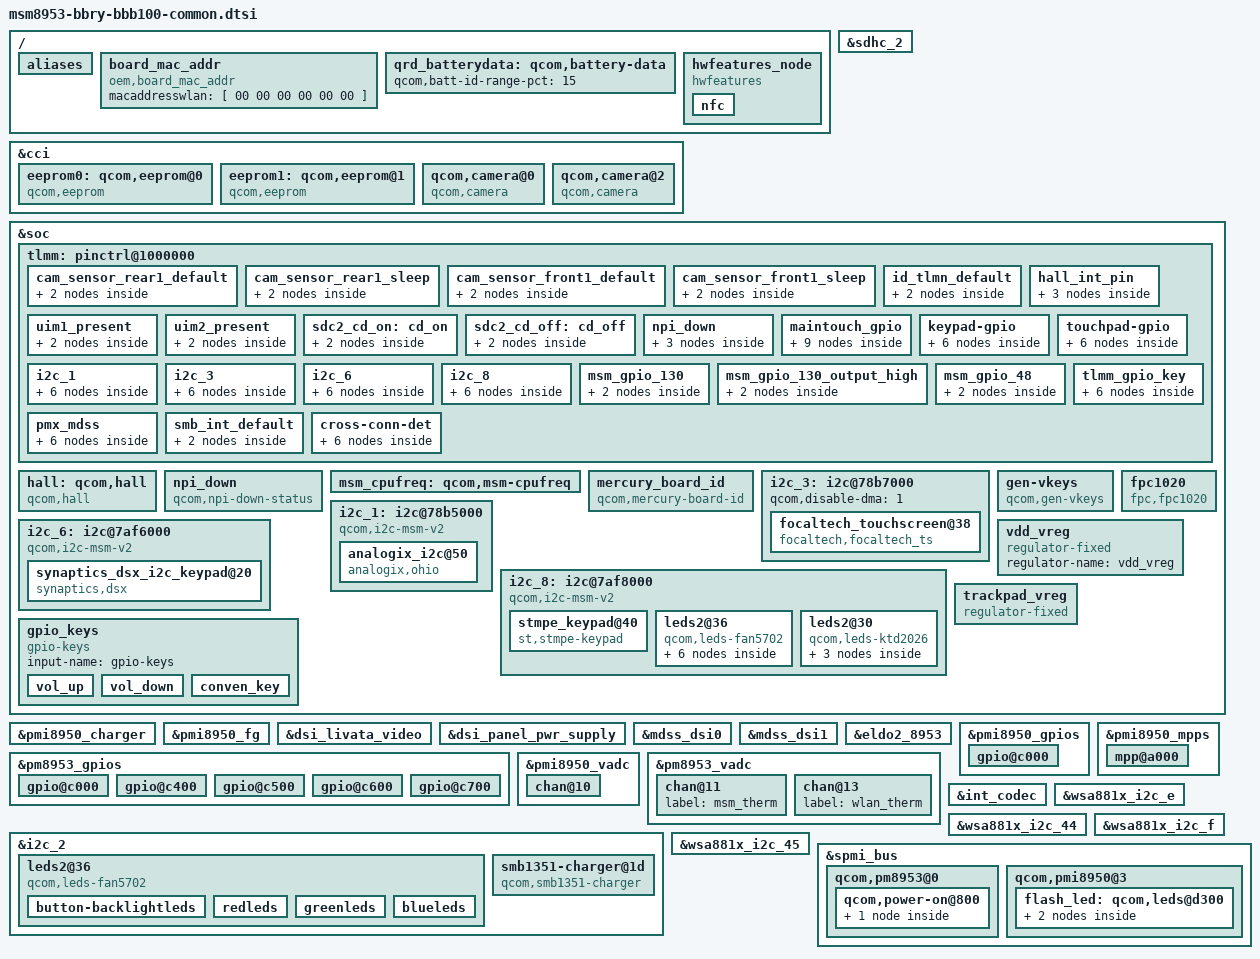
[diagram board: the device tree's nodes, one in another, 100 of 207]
/* Copyright (C) 2016 BlackBerry Limited. All rights reserved.
 * Copyright (c) 2014, The Linux Foundation. All rights reserved.
 *
 * This program is free software; you can redistribute it and/or modify
 * it under the terms of the GNU General Public License version 2 and
 * only version 2 as published by the Free Software Foundation.
 *
 * This program is distributed in the hope that it will be useful,
 * but WITHOUT ANY WARRANTY; without even the implied warranty of
 * MERCHANTABILITY or FITNESS FOR A PARTICULAR PURPOSE.  See the
 * GNU General Public License for more details.
 */

/*
 *  This DTSI is used for content that is common to all revisions of BBB100
 */
#include "dsi-panel-livata-video.dtsi"

/ {
	aliases {
		i2c1 = &i2c_1;
		i2c6 = &i2c_6;
		i2c8 = &i2c_8;
	};

	board_mac_addr {
		compatible = "oem,board_mac_addr";
		macaddresswlan = [ 00 00 00 00 00 00 ]; /* Filled by bootchain */
	};
};

&cci {
        /* MODIFIED-BEGIN by yongzhi.li, 2016-09-02,BUG-2641941*/
        /delete-node/qcom,eeprom@0;
        eeprom0: qcom,eeprom@0 {
		cell-index = <0>;
		compatible = "qcom,eeprom";
		qcom,cci-master = <0>;
		reg = <0x0>;
		cam_vio-supply = <&pm8953_l6>;
		cam_vdig-supply = <&pm8953_l2>;
		cam_vana-supply =  <&pm8953_l17>;
		qcom,cam-vreg-name = "cam_vio",  "cam_vdig",  "cam_vana";
		qcom,cam-vreg-min-voltage = <1800000 1100000 2850000>;
		qcom,cam-vreg-max-voltage = <1800000 1100000 2850000>;
		qcom,cam-vreg-op-mode = <0 105000 100000>;
		pinctrl-names = "cam_default", "cam_suspend";
		pinctrl-0 = <&cam_sensor_mclk0_default
				&cam_sensor_rear1_default>;
		pinctrl-1 = <&cam_sensor_mclk0_sleep &cam_sensor_rear1_sleep>;

		gpios = <&tlmm 26 0>,
			<&tlmm 40 0>,
			<&tlmm 35 0>;
		qcom,gpio-reset = <1>;
		qcom,gpio-vaf = <2>;
		qcom,gpio-req-tbl-num = <0 1 2>;
		qcom,gpio-req-tbl-flags = <1 0 0>;
		qcom,gpio-req-tbl-label = "CAMIF_MCLK0",
			"CAM_RESET0",
			"CAM_VAF";
		status = "ok";
		clocks = <&clock_gcc clk_mclk0_clk_src>,
				<&clock_gcc clk_gcc_camss_mclk0_clk>;
		clock-names = "cam_src_clk", "cam_clk";
		qcom,clock-rates = <24000000 0>;
	};
	/delete-node/qcom,eeprom@1;
         eeprom1: qcom,eeprom@1 {
		cell-index = <1>;
		reg = <0x1>;
		compatible = "qcom,eeprom";
		qcom,cci-master = <0>;
		cam_vdig-supply = <&pm8953_l23>;
		cam_vio-supply = <&pm8953_l6>;
                cam_vana-supply =  <&pm8953_l22>;
		qcom,cam-vreg-name = "cam_vdig", "cam_vio", "cam_vana";
		qcom,cam-vreg-min-voltage = <1200000 0 2800000>;
		qcom,cam-vreg-max-voltage = <1200000 0 2800000>;
		qcom,cam-vreg-op-mode = <105000 0 80000 >;
		pinctrl-names = "cam_default", "cam_suspend";
		pinctrl-0 = <&cam_sensor_mclk1_default
				&cam_sensor_front1_default>;
		pinctrl-1 = <&cam_sensor_mclk1_sleep &cam_sensor_front1_sleep>;
		gpios = <&tlmm 27 0>,
			<&tlmm 129 0>;
		qcom,gpio-reset = <1>;
		qcom,gpio-req-tbl-num = <0 1 >;
		qcom,gpio-req-tbl-flags = <1 0 >;
		qcom,gpio-req-tbl-label = "CAMIF_MCLK2",
			"CAM_RESET2";
		status = "ok";
		clocks = <&clock_gcc clk_mclk1_clk_src>,
				<&clock_gcc clk_gcc_camss_mclk1_clk>;
		clock-names = "cam_src_clk", "cam_clk";
		qcom,clock-rates = <19200000 0>;
	};
        /delete-node/qcom,camera@0;
        qcom,camera@0{
		cell-index = <0>;
		compatible = "qcom,camera";
		reg = <0x0>;
		qcom,csiphy-sd-index = <0>;
		qcom,csid-sd-index = <0>;
		qcom,mount-angle = <90>;
		qcom,led-flash-src = <&led_flash0>;
		qcom,eeprom-src = <&eeprom0>;
		qcom,actuator-src = <&actuator0>;
                cam_vio-supply = <&pm8953_l6>;
		cam_vdig-supply = <&pm8953_l2>;
		cam_vana-supply = <&pm8953_l17>;
		qcom,cam-vreg-name = "cam_vio", "cam_vdig", "cam_vana";
		qcom,cam-vreg-min-voltage = <1800000 1100000 2850000>;
		qcom,cam-vreg-max-voltage = <1800000 1100000 2850000>;
		qcom,cam-vreg-op-mode = <0   105000 100000>;
		pinctrl-names = "cam_default", "cam_suspend";
		pinctrl-0 = <&cam_sensor_mclk0_default
				&cam_sensor_rear1_default>;
		pinctrl-1 = <&cam_sensor_mclk0_sleep &cam_sensor_rear1_sleep>;
		gpios = <&tlmm 26 0>,
			<&tlmm 40 0>,
                        <&tlmm 35 0>;
		qcom,gpio-reset = <1>;
                qcom,gpio-vaf = <2>;
		qcom,gpio-req-tbl-num = <0 1 2>;
		qcom,gpio-req-tbl-flags = <1 0 0>;
		qcom,gpio-req-tbl-label = "CAMIF_MCLK0",
			"CAM_RESET0",
			"CAM_VAF";
		qcom,sensor-position = <0>;
		qcom,sensor-mode = <0>;
		qcom,cci-master = <0>;
		status = "ok";
		clocks = <&clock_gcc clk_mclk0_clk_src>,
				<&clock_gcc clk_gcc_camss_mclk0_clk>;
		clock-names = "cam_src_clk", "cam_clk";
		qcom,clock-rates = <24000000 0>;
	};
         /delete-node/qcom,camera@2;
	qcom,camera@2 {
		cell-index = <2>;
		compatible = "qcom,camera";
		reg = <0x02>;
		qcom,csiphy-sd-index = <2>;
		qcom,csid-sd-index = <2>;
		qcom,mount-angle = <90>;
                qcom,led-flash-src = <&led_flash0>; // MODIFIED by yongzhi.li, 2016-12-16,BUG-3767349
		qcom,eeprom-src = <&eeprom1>;
		qcom,actuator-src = <&actuator1>;
		cam_vdig-supply = <&pm8953_l23>;
		cam_vio-supply = <&pm8953_l6>;
		cam_vana-supply = <&pm8953_l22>;
		qcom,cam-vreg-name = "cam_vdig", "cam_vio", "cam_vana";
		qcom,cam-vreg-min-voltage = <1200000 0 2800000 >;
		qcom,cam-vreg-max-voltage = <1200000 0 2800000 >;
		qcom,cam-vreg-op-mode = <105000 0 80000 >;
		qcom,gpio-no-mux = <0>;
		pinctrl-names = "cam_default", "cam_suspend";
		pinctrl-0 = <&cam_sensor_mclk1_default
				&cam_sensor_front1_default>;
		pinctrl-1 = <&cam_sensor_mclk1_sleep
				&cam_sensor_front1_sleep>;
		gpios = <&tlmm 27 0>,
			<&tlmm 129 0>;
		qcom,gpio-reset = <1>;
		qcom,gpio-req-tbl-num = <0 1 >;
		qcom,gpio-req-tbl-flags = <1 0 >;
		qcom,gpio-req-tbl-label = "CAMIF_MCLK2",
					  "CAM_RESET2";
		qcom,sensor-position = <1>;
		qcom,sensor-mode = <0>;
		qcom,cci-master = <1>;
		status = "ok";
		clocks = <&clock_gcc clk_mclk1_clk_src>,
			<&clock_gcc clk_gcc_camss_mclk1_clk>;
		clock-names = "cam_src_clk", "cam_clk";
		qcom,clock-rates = <24000000 0>;
		/* MODIFIED-END by yongzhi.li,BUG-2641941*/
	};
};

/* Changes to msm8993-pinctrl.dtsi for bbry-bb100 platform */
&sdhc_2 {
	cd-gpios = <&tlmm 133 GPIO_ACTIVE_HIGH>;

	pinctrl-names = "active", "sleep", "onetime";
	pinctrl-2 = <&uim1_present &uim2_present>;
};

&tlmm {
	hall_int_pin {
		hall_default: hall_default {
			mux {
				pins = "gpio131", "gpio140";
				function = "gpio";
			};

			config {
				pins = "gpio131", "gpio140";
				drive-strength = <2>;
				bias-disable;
				input-enable;
			};
		};
	};

	uim1_present: uim1_present {
		mux {
			pins = "gpio54";
			function = "uim1_present";
		};

		config {
			pins = "gpio54";
			drive-strength = <2>;
			bias-pull-up;
		};
	};

	uim2_present: uim2_present {
		mux {
			pins = "gpio58";
			function = "uim2_present";
		};

		config {
			pins = "gpio58";
			drive-strength = <2>;
			bias-pull-up;
		};
	};

	sdc2_cd_on: cd_on {
		mux {
			pins = "gpio133";
			function = "gpio";
		};

		config {
			pins = "gpio133";
			drive-strength = <2>;
			bias-pull-up;
			input-enable;
		};
	};

	sdc2_cd_off: cd_off {
		mux {
			pins = "gpio133";
			function = "gpio";
		};

		config {
			pins = "gpio133";
			drive-strength = <2>;
			bias-pull-up;
			input-enable;
		};
	};

	npi_down {
		npi_down_default: npi_down_default{
			mux {
				pins = "gpio89";
				function = "gpio";
			};

			config {
				pins = "gpio89";
				drive-strength = <2>; /* 2 mA */
				bias-pull-up; /* pull up */
				input-enable;
			};
		};
	};
	maintouch_gpio {
		focaltech_irq: focaltech_irq {
			mux {
				pins = "gpio65";
				function = "gpio";
			};

			config {
				pins = "gpio65";
				drive-strength = <2>;
				bias-pull-up;
			};
		};

		focaltech_reset: focaltech_reset {
			mux {
				pins = "gpio64";
				function = "gpio";
			};

			config {
				pins = "gpio64";
				drive-strength = <2>;
				bias-pull-up;
			};
		};

		focaltech_input: focaltech_input {
			mux {
				pins = "gpio85", "gpio86", "gpio87";
				function = "gpio";
			};

			config {
				pins = "gpio85", "gpio86", "gpio87";
				drive-strength = <2>;
				bias-pull-up;
			};
		};
	};

	/* KEYPAD INTERRUPT */
	keypad-gpio {
		keypad_int_default: keypad_int_default {
			mux {
				pins = "gpio12";
				function = "gpio";
			};

			config {
				pins = "gpio12";
				drive-strength = <2>;
				bias-pull-up;
			};
		};
		keypad_reset_default: keypad_reset_default {
			mux {
				pins = "gpio66";
				function = "gpio";
			};

			config {
				pins = "gpio66";
				drive-strength = <2>;
				bias-pull-up;
			};
		};
	};

	touchpad-gpio {
		touchpad_int_default: touchpad_int_default {
			mux {
				pins = "gpio21";
				function = "gpio";
			};

			config {
				pins = "gpio21";
				drive-strength = <2>;
				bias-pull-up;
			};
		};
		touchpad_reset: touchpad_reset {
			mux {
				pins = "gpio20";
				function = "gpio";
			};

			config {
				pins = "gpio20";
				drive-strength = <2>;
				bias-pull-up;
			};
		};
	};

	i2c_1 {
		i2c_1_active: i2c_1_active {
			mux {
				pins = "gpio2", "gpio3";
				function = "blsp_i2c1";
			};
			config {
				pins = "gpio2", "gpio3";
				drive-strength = <2>;
				bias-disable;
			};
		};

		i2c_1_sleep: i2c_1_sleep {
			mux {
				pins = "gpio2", "gpio3";
				function = "blsp_i2c1";
			};
			config {
				pins = "gpio2", "gpio3";
				drive-strength = <2>;
				bias-pull-up;
			};
		};
	};

	i2c_3 {
		i2c_3_active: i2c_3_active {
			/* active state */
			mux {
				pins = "gpio10", "gpio11";
				function = "blsp_i2c3";
			};

			config {
				pins = "gpio10", "gpio11";
				drive-strength = <2>;
				bias-disable;
			};
		};

		i2c_3_sleep: i2c_3_sleep {
			/* suspended state */
			mux {
				pins = "gpio10", "gpio11";
				function = "blsp_i2c3";
			};

			config {
				pins = "gpio10", "gpio11";
				drive-strength = <2>;
				bias-disable;
			};
		};
	};

	i2c_6 {
		i2c_6_active: i2c_6_active {
			/* active state */
			mux {
				pins = "gpio22", "gpio23";
				function = "blsp_i2c6";
			};

			config {
				pins = "gpio22", "gpio23";
				drive-strength = <2>;
				bias-disable;
			};
		};

		i2c_6_sleep: i2c_6_sleep {
			/* suspended state */
			mux {
				pins = "gpio22", "gpio23";
				function = "blsp_i2c6";
			};

			config {
				pins = "gpio22", "gpio23";
				drive-strength = <2>;
				bias-disable;
			};
		};
	};

	i2c_8 {
		i2c_8_active: i2c_8_active {
			/* active state */
			mux {
				pins = "gpio98", "gpio99";
				function = "blsp_i2c8";
			};

			config {
				pins = "gpio99", "gpio98";
				drive-strength = <2>;
				bias-disable;
			};
		};

		i2c_8_sleep: i2c_8_sleep {
			/* suspended state */
			mux {
				pins = "gpio98", "gpio99";
				function = "blsp_i2c8";
			};

			config {
				pins = "gpio99", "gpio98";
				drive-strength = <2>;
				bias-disable;
			};
		};
	};

	/* GPIO_130 : FP_RESET_N */
	msm_gpio_130: msm_gpio_130 {
		mux {
		        pins = "gpio130";
               		function = "gpio";
		};

		config {
		        pins = "gpio130";
		        drive-strength = <2>;
		        bias-disable;
		        output-low;
		};
       	};

       	/* GPIO_130 : FP_RESET_N, state device active*/
        msm_gpio_130_output_high: msm_gpio_130_output_high {
		mux {
		        pins = "gpio130";
		        function = "gpio";
		};

		config {
		        pins = "gpio130";
		        drive-strength = <2>;
                       	bias-disable;
       	                output-high;
               	};
       	};

        /* GPIO_48 : FP_INT_N */
       	msm_gpio_48: msm_gpio_48 {
		mux {
                       	pins = "gpio48";
                       	function = "gpio";
               	};

		config {
                       	pins = "gpio48";
                       	drive-strength = <2>;
                       	bias-pull-down;
                };
	};

	tlmm_gpio_key {
		gpio_key_active: gpio_key_active {
			mux {
				/* MODIFIED-BEGIN by Haojun Chen, 2016-11-29,BUG-3620552*/
				pins = "gpio85", "gpio87", "gpio88";
				function = "gpio";
			};

			config {
				pins = "gpio85", "gpio87", "gpio88";
				/* MODIFIED-END by Haojun Chen,BUG-3620552*/
				drive-strength = <2>;
				bias-pull-up;
			};
		};

		gpio_key_suspend: gpio_key_suspend {
			mux {
				/* MODIFIED-BEGIN by Haojun Chen, 2016-11-29,BUG-3620552*/
				pins = "gpio85", "gpio87", "gpio88";
				function = "gpio";
			};

			config {
				pins = "gpio85", "gpio87", "gpio88";
				/* MODIFIED-END by Haojun Chen,BUG-3620552*/
				drive-strength = <2>;
				bias-pull-up;
			};
		};
	};
};

&soc {
        tlmm: pinctrl@1000000{
                cam_sensor_rear1_default: cam_sensor_rear1_default {
			/* RESET, STANDBY */
			mux {
				pins = "gpio40", "gpio39", "gpio35";
				function = "gpio";
			};

			config {
				pins = "gpio40","gpio39", "gpio35";
				bias-disable; /* No PULL */
				drive-strength = <2>; /* 2 MA */
			};
		};

		cam_sensor_rear1_sleep: cam_sensor_rear1_sleep {
			/* RESET, STANDBY */
			mux {
				pins = "gpio40","gpio39", "gpio35";
				function = "gpio";
			};

			config {
				pins = "gpio40","gpio39", "gpio35";
				bias-disable; /* No PULL */
				drive-strength = <2>; /* 2 MA */
			};
		};

                /* MODIFIED-BEGIN by yongzhi.li, 2017-03-14,BUG-4304800*/
                /delete-node/cam_sensor_front1_default;
                cam_sensor_front1_default: cam_sensor_front1_default {  //yongzhi
			/* RESET, STANDBY */
			mux {
				pins = "gpio129";
				function = "gpio";
			};

			config {
				pins = "gpio129";
				bias-disable; /* No PULL */
				drive-strength = <2>; /* 2 MA */
			};
		};

                /delete-node/cam_sensor_front1_sleep;
		cam_sensor_front1_sleep: cam_sensor_front1_sleep {
			/* RESET, STANDBY */
			mux {
				pins = "gpio129";
				function = "gpio";
			};

			config {
				pins = "gpio129";
				bias-disable; /* No PULL */
				drive-strength = <2>; /* 2 MA */
			};
		};
		/* MODIFIED-END by yongzhi.li,BUG-4304800*/

		id_tlmn_default: id_tlmn_default {
			mux {
				pins = "gpio44","gpio46", "gpio47";
				function = "gpio";
			};

			config {
				pins = "gpio44","gpio46", "gpio47";
				drive-strength = <2>;
				bias-disable;
			};
		};
       };
	hall:qcom,hall {
		cell-index = <0>;
		compatible = "qcom,hall";
		interrupt-parent = <&tlmm>;
		interrupts = <131 0x3> , <140 0x3>;
		interrupt-gpios = <&tlmm 131 0x00> , <&tlmm 140 0x00>;
		vdd-supply = <&pm8953_l6>;
		qcom,vdd-always-on;  /* For now keep supply always on */
		pinctrl-names = "default";
		pinctrl-0 = <&hall_default>;
	};
	npi_down{
			compatible = "qcom,npi-down-status";
			qcom,npi-down-gpio = <&tlmm 89 0>;
			pinctrl-names = "default";
			pinctrl-0 = <&npi_down_default>;
	};
	msm_cpufreq: qcom,msm-cpufreq {
		qcom,cpufreq-table =
			 <  652800 >,
			 < 1036800 >,
			 < 1401600 >,
			 < 1689600 >,
			 < 1804800 >, // MODIFIED by xin.peng, 2017-02-16,BUG-3856467
			 < 1958400 >,
			 < 2016000 >;
	};
	mercury_board_id{
			compatible = "qcom,mercury-board-id";
			qcom,board-id-gpio1 = <&tlmm 44 0>;
			qcom,board-id-gpio2 = <&tlmm 46 0>;
			qcom,board-id-gpio3 = <&tlmm 47 0>;

			pinctrl-names = "id_default";
			pinctrl-0 = <&id_tlmn_default>;
	};
	i2c_3: i2c@78b7000 { /* BLSP1 QUP3 */
		qcom,disable-dma = <1>;
		status = "okay";

		focaltech_touchscreen@38 {
			compatible = "focaltech,focaltech_ts";
			reg = <0x38>;
			/*interrupt-parent = <&msm_gpio>;*/
			/*interrupts = <13 0x8>;*/
			pinctrl-names = "on_state", "off_state";
			pinctrl-0 = <&ts_int_active>;
			pinctrl-1 = <&ts_int_suspend>;

			disp_1p8-supply     	= <&vdd_vreg>;
			disp_p5v-supply 	= <&lab_regulator>;
			disp_n5v-supply 	= <&ibb_regulator>;
			oem,disp-rst-n-gpio = <&tlmm 61 0x00>;
			oem,tscrn-rst-n-gpio = <&tlmm 64 0x00>;
			oem,disp-1p8-en-gpio = <&tlmm 50 0x00>;
			/* MODIFIED-BEGIN by Haojun Chen, 2016-11-29,BUG-3620552*/
			oem,disp-n5v-en-gpio = <&tlmm 1 0x00>;
			oem,disp-p5v-en-gpio = <&tlmm 86 0x00>;
			/* MODIFIED-END by Haojun Chen,BUG-3620552*/
			focaltech,reset-gpio = <&tlmm 64 0x00>;
			focaltech,irq-gpio = <&tlmm 65 0x00>;

			focaltech,name = "fts";
			focaltech,family-id = <0x54>;

			focaltech,x-resolution = <1080>;
			focaltech,y-resolution = <1620>;
			focaltech,display-coords = <0 0 1080 1640>;
			focaltech,panel-coords = <0 0 1080 1640>;
			focaltech,button-map= <180 360 540>;
			focaltech,no-force-update;
			focaltech,i2c-pull-up;
			focaltech,group-id = <1>;
			focaltech,hard-reset-delay-ms = <20>;
			focaltech,soft-reset-delay-ms = <150>;
			focaltech,num-max-touches = <10>;
			focaltech,fw-name = "FT_Upgrade_App.i";
			focaltech,fw-delay-aa-ms = <50>;
			focaltech,fw-delay-55-ms = <30>;
			focaltech,fw-upgrade-id1 = <0x79>;
			focaltech,fw-upgrade-id2 = <0x03>;
			focaltech,fw-delay-readid-ms = <10>;
			focaltech,fw-delay-era-flsh-ms = <2000>;
			status = "okay";
		};
	};

	gen-vkeys {
		compatible = "qcom,gen-vkeys";
		label = "fts_input_device_B";
		qcom,disp-maxx = <1080>;
		qcom,disp-maxy = <1620>;
		qcom,panel-maxx = <1080>;
		qcom,panel-maxy = <1700>;
		/* qcom,key-codes = <139 172 158>; */
		qcom,key-codes = <158 172 580>;
		qcom,y-offset = <0>;
	};

#if 1
	/* ANX7408 - USB Type-C  */
	i2c_1: i2c@78b5000 { /* BLSP1 QUP1 */
		compatible = "qcom,i2c-msm-v2";
		#address-cells = <1>;
		#size-cells = <0>;
		reg-names = "qup_phys_addr";
		reg = <0x78b5000 0x600>;
		interrupt-names = "qup_irq";
		interrupts = <0 95 0>;
		qcom,clk-freq-out = <400000>;
		qcom,clk-freq-in  = <19200000>;
		clock-names = "iface_clk", "core_clk";
		clocks = <&clock_gcc clk_gcc_blsp1_ahb_clk>,
			<&clock_gcc clk_gcc_blsp1_qup1_i2c_apps_clk>;
		pinctrl-names = "i2c_active", "i2c_sleep";
		pinctrl-0 = <&i2c_1_active>;
		pinctrl-1 = <&i2c_1_sleep>;
		qcom,noise-rjct-scl = <0>;
		qcom,noise-rjct-sda = <0>;
		qcom,master-id = <86>;
		/* qcom,disable-dma = <1>; */
		dmas = <&dma_blsp1 4 64 0x20000020 0x20>,
			<&dma_blsp1 5 32 0x20000020 0x20>;
		dma-names = "tx", "rx";

		analogix_i2c@50{
			compatible ="analogix,ohio";
			status = "ok";
			reg = <0x50>;
			interrupt-parent = <&tlmm>;
			interrupts = <9 0>; //cable_det gpio is interrupt pin

			analogix,p-on-gpio = <&tlmm 92 0x0>; //PWR_EN
			analogix,reset-gpio = <&tlmm 93 0x00>; //RESET
			analogix,intr-comm-gpio = <&tlmm 91 0x0>; //INTP
			analogix,cbl-det-gpio = <&tlmm 9 0x0>; //CABLE_DET
			analogix,vbus-ctrl-gpio = <&tlmm 90 0x0>; // ADD by TCTNB.YQJ, 2016-12-01,task-3562699
			analogix,vcon-pwr-en = <&tlmm 0 0x0>; //VCONN_USB_HOST_PWR_EN
			analogix,unused-usbid = <&pm8953_gpios 8 0x00>; // ADD by TCTNB.YQJ, 2016-12-13,task-3714398
			analogix.external-ldo-control = <1>;
			analogix,i2c-pull-up = <1>;
		};
	};
#endif

	i2c_6: i2c@7af6000 { /* BLSP2 QUP1 */
		compatible = "qcom,i2c-msm-v2";
		#address-cells = <1>;
		#size-cells = <0>;
		reg-names = "qup_phys_addr";
		reg = <0x7af6000 0x600>;
		interrupt-names = "qup_irq";
		interrupts = <0 300 0>;
		qcom,clk-freq-out = <400000>;
		qcom,clk-freq-in  = <19200000>;
		clock-names = "iface_clk", "core_clk";
		clocks = <&clock_gcc clk_gcc_blsp2_ahb_clk>,
			<&clock_gcc clk_gcc_blsp2_qup2_i2c_apps_clk>;
		pinctrl-names = "i2c_active", "i2c_sleep";
		pinctrl-0 = <&i2c_6_active>;
		pinctrl-1 = <&i2c_6_sleep>;
		qcom,noise-rjct-scl = <0>;
		qcom,noise-rjct-sda = <0>;
		qcom,master-id = <84>;
		/* qcom,disable-dma = <1>; */
		dmas = <&dma_blsp2 6 64 0x20000020 0x20>,
			<&dma_blsp2 7 32 0x20000020 0x20>;
		dma-names = "tx", "rx";

		/* Synatic keypad touch */
		synaptics_dsx_i2c_keypad@20 {
			compatible = "synaptics,dsx";
			reg = <0x20>;
			synaptics,reg-en;
			vcc-supply = <&pm8953_l6>;  /* 1.8v */
			vcc_2p8v-supply = <&pm8953_l10>;  /* 2.8v */
			synaptics,reset-gpio = <&tlmm 20 0x00>;
			synaptics,irq-gpio = <&tlmm 21 0x00>;
			/* synaptics,irq-on-state = <0>; */
			/* synaptics,power-gpio = <&pm8953_gpios 5 0x3>; */
			/* synaptics,main-power-gpio = <&pm8953_gpios 5 0x3>; */
			synaptics,power-on-status = <1>;
			synaptics,main-power-on-status = <1>;
			synaptics,report-type = <78>;
			synaptics,product-id-major = "63022";
			synaptics,disable-baseline-compensation-in-BIST = <0>;
			pinctrl-names = "default";
			pinctrl-0 = <&touchpad_int_default>;
			synaptics,x-flip = <0>;
			synaptics,y-flip = <0>;
			synaptics,reset-on-status = <0>;
			synaptics,power-delay-ms = <1>;
			synaptics,reset-delay-ms = <63>;
			synaptics,reset-active-ms = <15>;
			synaptics,watchdog-timeout-s = <10>;
			synaptics,bist-min = <1980>;
			synaptics,bist-max = <6000>;
			synaptics,input-device-name = "touch_keypad";
			synaptics,resolution_x = <21>;
			synaptics,resolution_y = <21>;
			synaptics,power-gpio1 = <&pm8953_gpios 5 0>;
			synaptics,power-gpio2 = <&pm8953_gpios 6 0>;
			synaptics,power-gpio3 = <&pmi8950_gpios 1 0>;
			synaptics,panel_y = <324>;
			synaptics,num_of_rx_electrodes = <9>;
			synaptics,num_of_tx_electrodes = <3>;
		};
	};


	i2c_8: i2c@7af8000 { /* BLSP2 QUP3 */
		compatible = "qcom,i2c-msm-v2";
		#address-cells = <1>;
		#size-cells = <0>;
		reg-names = "qup_phys_addr";
		reg = <0x7af8000 0x600>;
		interrupt-names = "qup_irq";
		interrupts = <0 302 0>;
		qcom,clk-freq-out = <400000>;
		qcom,clk-freq-in  = <19200000>;
		clock-names = "iface_clk", "core_clk";
		clocks = <&clock_gcc clk_gcc_blsp2_ahb_clk>,
			<&clock_gcc clk_gcc_blsp2_qup4_i2c_apps_clk>;
		pinctrl-names = "i2c_active", "i2c_sleep";
		pinctrl-0 = <&i2c_8_active>;
		pinctrl-1 = <&i2c_8_sleep>;
		qcom,noise-rjct-scl = <0>;
		qcom,noise-rjct-sda = <0>;
		qcom,master-id = <84>;
		/* qcom,disable-dma = <1>;  */
		dmas = <&dma_blsp2 10 64 0x20000020 0x20>,
			<&dma_blsp2 11 32 0x20000020 0x20>;
		dma-names = "tx", "rx";
		status = "okay";

		/* STMPE 1801 Keypad */
		stmpe_keypad@40 {
			compatible = "st,stmpe-keypad";
			reg = <0x40>;
/*			st,vdd-supply =  <&pm8953_l10>; */
/*			st,vdd-gpio = <&pm8953_gpios 06 0x3>; */
			st,keypad-rst-int = <&tlmm 13 0x00>;
			st,keypad-kp-int = <&tlmm 12 0x00>;
			st,keypad-reset = <&tlmm 66 0x3>;
			st,scan-count = <2>;
			st,debounce = <10>;
			st,scan-frequency = <60>;
			st,check-inadv = <0x39>;
			st,inadv-timeout = <200>;
			st,key-count = <0x0e>;
			pinctrl-names = "default";
			pinctrl-0 = <&keypad_int_default>;
			linux,keymap = <0x3010010 0x3070011 0x4010012 0x5010013
					0x5040014 0x6040015 0x6010016 0x7040017
					0x7010018 0x4020019 0x304001e 0x407001f
					0x4040020 0x5050021 0x5070022 0x6070023
					0x6050024 0x7050025 0x7070026 0x702000e
					0x3060038 0x400002c 0x406002d 0x500002e
					0x506002f 0x6060030 0x6000031 0x7000032
					0x7060005 0x602001c 0x405002a 0x305000b
					0x3000039 0x3020064 0x5020036>;
			st,physical_keymap = <0x1010010 0x1020011 0x1030012 0x1040013
					0x1050014 0x1060015 0x1070016 0x1080017
					0x1090018 0x10a0019 0x201001e 0x202001f
					0x2030020 0x2040021 0x2050022 0x2060023
					0x2070024 0x2080025 0x2090026 0x20a000e
					0x3010038 0x302002c 0x303002d 0x304002e
					0x305002f 0x3060030 0x3070031 0x3080032
					0x3090005 0x30a001c 0x4010000 0x402002a
					0x403000b 0x4040039 0x4050039 0x4060039
					0x4070039 0x4080064 0x4090036>;
		};
	};

	fpc1020 {
		status = "ok";
		compatible = "fpc,fpc1020";
		interrupt-parent = <&tlmm>;
		interrupts = <78 0x0>;
		fpc,gpio_rst    = <&tlmm 130 0x0>;
		fpc,gpio_irq    = <&tlmm 48 0x0>;
		/* fpc,gpio_pwr    = <&tlmm 92 0x0>; */
		vdd_ana-supply  = <&pm8953_l6>;
		fpc,enable-on-boot;
		fpc,enable-wakeup;
		pinctrl-names = "fpc1020_reset_reset",
		        "fpc1020_reset_active",
		        "fpc1020_irq_active";

		pinctrl-0 = <&msm_gpio_130>;
		pinctrl-1 = <&msm_gpio_130_output_high>;
		pinctrl-2 = <&msm_gpio_48>;
	};

	vdd_vreg: vdd_vreg {
		compatible = "regulator-fixed";
		status = "ok";
		regulator-name = "vdd_vreg";
	};

	/delete-node/clock_audio;
	/delete-node/cdc_mclk2_pin;

	/* Delete unused quinary MI2S pinctrl nodes (pri-tlmm-lines and pri-tlmm-ws-lines) */
	/delete-node/pri-tlmm-lines;
	/delete-node/pri-tlmm-ws-lines;

	trackpad_vreg: trackpad_vreg {
		compatible = "regulator-fixed";
		regulator-name = "trackpad_vreg";
		startup-delay-us = <0>;
		enable-active-high;
		gpio = <&pm8953_gpios 5 0>;
		regulator-always-on;
	};

	gpio_keys {
		compatible = "gpio-keys";
		input-name = "gpio-keys";

		/delete-node/camera_focus;
		/delete-node/camera_snapshot;

		vol_up {
			label = "volume_up";
			gpios = <&tlmm 85 0x1>;
			linux,input-type = <1>;
			linux,code = <115>;
			debounce-interval = <15>;
		};

		vol_down {
			label = "volume_down";
			gpios = <&tlmm 87 0x1>;
			linux,input-type = <1>;
			linux,code = <114>;
			debounce-interval = <15>;
		};

		conven_key {
			label = "conven_key";
			gpios = <&tlmm 88 0x1>;
			linux,input-type = <1>;
			linux,code = <550>;
			debounce-interval = <15>;
		};
	};
};

/ {
	qrd_batterydata: qcom,battery-data {
		qcom,batt-id-range-pct = <15>;
		#include "batterydata-hermes-4v4-3440mah.dtsi"
		#include "batterydata-byd-4v4-3440mah.dtsi"
	};
};

&tlmm {
	/delete-node/pmx_mdss;
	pmx_mdss: pmx_mdss {
		mdss_dsi_active: mdss_dsi_active {
			mux {
				pins = "gpio61";
				function = "gpio";
			};

			config {
				pins = "gpio61";
				drive-strength = <8>; /* 8 mA */
				bias-disable = <0>; /* no pull */
				output-high;
			};
		};

		mdss_dsi_suspend: mdss_dsi_suspend {
			mux {
				pins = "gpio61";
				function = "gpio";
			};

			config {
				pins = "gpio61";
				drive-strength = <2>; /* 2 mA */
				bias-pull-down; /* pull down */
			};
		};
	};

	smb_int_default: smb_int_default {
		mux {
			pins = "gpio59";
			function = "gpio";
		};

		config {
			pins = "gpio59";
			drive-strength = <2>; /* 2 mA */
			bias-pull-up; /* pull up */
		};
	};
};

&pmi8950_charger {
	/delete-property/ qcom,external-typec;
	/delete-property/ qcom,typec-psy-name;
	/delete-property/ qcom,force-aicl-rerun;
	/delete-property/ qcom,aicl-rerun-period-s;
	/delete-property/ qcom,autoadjust-vfloat;
	/delete-property/ qcom,chg-led-support;
	/delete-property/ qcom,chg-led-sw-controls;
	/delete-property/ qcom,fastchg-current-ma;

	qcom,battery-data = <&qrd_batterydata>;
	qcom,charging-timeout-mins = <1536>;
	qcom,precharging-timeout-mins = <48>;
	qcom,iterm-ma = <100>;
	qcom,float-voltage-mv = <4400>;

	qcom,thermal-mitigation = <3000 2500 2000 1500 1000 500 0>;
	status = "okay";
	qcom,parallel-usb-min-current-ma = <1400>;
	qcom,parallel-usb-9v-min-current-ma = <900>;
	qcom,parallel-allowed-lowering-ma = <500>;

	qcom,parallel-main-chg-fcc-percent = <45>;
	qcom,parallel-main-chg-icl-percent = <50>;
	qcom,skip-usb-suspend-for-fake-battery;
	qcom,disable-parallel-uv = <3900000>;

	qcom,jeita-temp-hard-limit = <1>;
	qcom,resume-delta-mv = <200>;

	pinctrl-names = "smb_int_default";
	pinctrl-0 = <&smb_int_default>;
	stat-gpio = <&tlmm 59 0x2>;

	qcom,charge-unknown-battery;
};

&pmi8950_fg {
	/delete-property/ qcom,resume-soc;
	qcom,resume-soc-raw = <0xFD>;
	qcom,vbat-estimate-diff-mv = <200>;

	qcom,capacity-learning-feedback;
	qcom,hold-soc-while-full;

	qcom,battery-data = <&qrd_batterydata>;
	qcom,irq-volt-empty-mv = <3100>;
	qcom,fg-cutoff-voltage-mv = <3350>;

	qcom,ext-sense-type;
	qcom,fg-iterm-ma = <250>;
	qcom,fg-chg-iterm-ma = <100>;

	/* JEITA */
	qcom,cold-bat-decidegc = <10>;
	qcom,cool-bat-decidegc = <100>;
	qcom,warm-bat-decidegc = <450>;
	qcom,hot-bat-decidegc = <550>;

	qcom,cold-hot-jeita-hysteresis = <20 20>;
	qcom,cool-warm-jeita-hysteresis = <20 20>;
};

&dsi_livata_video {
	qcom,panel-supply-entries = <&dsi_panel_pwr_supply>;
	qcom,mdss-dsi-panel-timings-phy-v2 = [22 1e 07 08 04 03 04 a0
		22 1e 07 08 04 03 04 a0
		22 1e 07 08 04 03 04 a0
		22 1e 07 08 04 03 04 a0
		22 18 07 08 04 03 04 a0];
};

&dsi_panel_pwr_supply {
	/* On Mercury, The touch driver controls vregs and gpios */
	/delete-node/ qcom,panel-supply-entry@1;
	/delete-node/ qcom,panel-supply-entry@2;
	/delete-node/ qcom,panel-supply-entry@3;
};

&mdss_dsi0 {
	/* On Mercury, The touch driver controls vregs and gpios */
	/delete-property/ vddio-supply;
	/delete-property/ lab-supply;
	/delete-property/ ibb-supply;
	/delete-property/ vdd-supply;

	/delete-property/ qcom,platform-enable-gpio;
	/delete-property/ qcom,5v-boost-gpio;
	/delete-property/ qcom,platform-bklight-en-gpio;
	/delete-property/ qcom,platform-reset-gpio;
};

&mdss_dsi1 {
	/* On Mercury, The touch driver controls vregs and gpios */
	/delete-property/ vddio-supply;
	/delete-property/ lab-supply;
	/delete-property/ ibb-supply;
	/delete-property/ vdd-supply;

	/delete-property/ qcom,platform-enable-gpio;
	/delete-property/ qcom,5v-boost-gpio;
	/delete-property/ qcom,platform-bklight-en-gpio;
	/delete-property/ qcom,platform-reset-gpio;
};


&eldo2_8953 {
	/* msm8953-regulator.dtsi defines gpio50 as the enable gpio for this ldo.
	 * is the case on QRD, but not on Mercury. On Mercury, this GPIO is the DISP_1P8
	 * enabled line. Remove this here to avoid collisions.
	 */
	/delete-property/ gpio;
};

&pm8953_gpios {
	gpio@c000 {
		qcom,mode = <1>;
		qcom,output-type = <0>;
		qcom,out-strength = <3>;
		qcom,master-en = <1>;
		qcom,src-sel = <0>;
		status = "okay";
	};

	gpio@c400 {
		/* KEYPAD_1P8_EN */
		qcom,mode = <1>;
		qcom,output-type = <1>;
		qcom,out-strength = <3>;
		qcom,src-sel = <1>;
		qcom,pull = <0>;
		qcom,master-en = <1>;
		qcom,invert = <1>;
		status = "okay";
	};

	gpio@c500 {
		qcom,mode = <1>;
		qcom,output_type = <1>;
		qcom,out-strength = <3>;
		qcom,src-sel = <1>;
		qcom,master-en = <1>;
		qcom,invert = <1>;
		status = "okay";
	};

	gpio@c600 {
		/* used by fan5702 led controller (NAV_BL_EN) */
		qcom,mode = <1>;
		qcom,output-type = <0>;
		qcom,out-strength = <3>;
		qcom,src-sel = <0>;
		qcom,master-en = <1>;
		status = "okay";
	};
/*ADD Begin by TCTNB.YQJ, 2016-12-13,task-3714398 */
	gpio@c700 {
		qcom,mode = <0>;
		qcom,output-type = <0>;
		qcom,pull = <0>;
		qcom,vin-sel = <2>;
		qcom,out-strength = <3>;
		qcom,src-sel = <0>;
		qcom,master-en = <1>;
		status = "okay";
	};
/* ADD End by TCTNB.YQJ ,task-3714398 */
};

&pmi8950_gpios {
	gpio@c000 {
		/* used by fan5702 led controller (KEYPAD_BL_EN) */
		qcom,mode = <1>;
		qcom,output_type = <0>;
		qcom,out-strength = <3>;
		qcom,src-sel = <0>;
		qcom,master-en = <1>;
		status = "okay";
	};
};

&pmi8950_mpps {
	mpp@a000 {
		qcom,mode = <4>;
		qcom,invert = <1>;
		qcom,ain-route = <0>;
		qcom,master-en = <1>;
		qcom,src-sel = <0>;
		status = "okay"; // MODIFIED by xin.peng, 2017-01-10,BUG-3992379
	};
};

&pmi8950_vadc {
       chan@10 {
               label = "ambient_therm";
               reg = <0x10>;
               qcom,decimation = <0>;
               qcom,pre-div-channel-scaling = <0>;
               qcom,calibration-type = "ratiometric";
               qcom,scale-function = <2>;
               qcom,hw-settle-time = <9>; // MODIFIED by hongwei.tian, 2017-03-29,BUG-4444994
               qcom,fast-avg-setup = <0>;
               qcom,vadc-thermal-node;
       };
};

&pm8953_vadc {
       chan@11 {
               label = "msm_therm";
       };

       chan@13 {
               label = "wlan_therm";
       };
};

&i2c_2{
	//#address-cells = <1>;
	//#size-cells = <0>;
	leds2@36 {
		compatible = "qcom,leds-fan5702";
		linux,name = "nav+rgb";
		reg = <0x36>;
		led,delay_on = <500>;
		led,delay_off = <3500>;
		en-gpio = <&pm8953_gpios 7 0>;
		button-backlightleds{
			linux,name = "button-backlight";
			led,mask = /bits/ 8 <0x03>;
			led,max_brightness = <0x3F>;
		};
		redleds{
			linux,name = "red";
			led,mask = /bits/ 8 <0x10>;
			led,max_brightness = <0x3D>;
			led,use-blink;
		};
		greenleds{
			linux,name = "green";
			led,mask = /bits/ 8 <0x04>;
			led,max_brightness = <0x27>;
			led,use-blink;
		};
		blueleds{
			linux,name = "blue";
			led,mask = /bits/ 8 <0x08>;
			led,max_brightness = <0x31>;
			led,use-blink;
		};
	};
};

	/* Parallel-charger configuration */
&i2c_2{
	status = "ok";
	smb1351-charger@1d {
		compatible = "qcom,smb1351-charger";
		reg = <0x1d>;
		qcom,parallel-en-pin-polarity = <1>;
		qcom,parallel-charger;
		qcom,float-voltage-mv = <4400>;
		qcom,recharge-mv = <100>;
		oem,otg-oc-limit-idx = <0>;   /* 0-1800, 1-500, 2-750, 3-1000, unit: mA */
		oem,otg-uvlo-limit-idx = <3>; /* 0-2.7, 1-2.9, 2-3.1, 3-3.3, unit: V */
	};
};


&i2c_8{
	leds2@36 {
		compatible = "qcom,leds-fan5702";
		linux,name = "kp+fp";
		reg = <0x36>;
		led,delay_on = <500>;
		led,delay_off = <3500>;
		en-gpio = <&pmi8950_gpios 1 0>;
		i2c-en-gpio = <&pm8953_gpios 5 0>;
		i2c-supply = <&pm8953_l6>;
		fingerprint-backlightleds{
			linux,name = "fingerprint-backlight";
			led,mask = /bits/ 8 <0x01>;
			led,max_brightness = <0x3F>;
		};
		keyboard-backlightleds{
			linux,name = "keyboard-backlight";
			led,mask = /bits/ 8 <0x1E>;
			led,max_brightness = <0x3F>;
		};
/* [BUGFIX]-Add- by TCLNB.XQJ,bug 3408116,11/14,add keypad backlight control four led*/
        keyboard-backlightled_1{
			linux,name = "keyboard-backlight_1";
			led,mask = /bits/ 8 <0x02>;
			led,max_brightness = <0x3F>;
		};
		keyboard-backlightled_2{
			linux,name = "keyboard-backlight_2";
			led,mask = /bits/ 8 <0x04>;
			led,max_brightness = <0x3F>;
		};
		keyboard-backlightled_3{
			linux,name = "keyboard-backlight_3";
			led,mask = /bits/ 8 <0x08>;
			led,max_brightness = <0x3F>;
		};
		keyboard-backlightled_4{
			linux,name = "keyboard-backlight_4";
			led,mask = /bits/ 8 <0x10>;
			led,max_brightness = <0x3F>;
		};
/* [BUGFIX]-End- by TCLNB.XQJ*/

	};
/* [PLATFORM]-Add- by TCTNB.XQJ, RR-3902379, 2017/1/5, add led ic ktd2026 for mercury	*/
 leds2@30 {
		compatible = "qcom,leds-ktd2026";
		linux,name = "ktd2026";
		reg = <0x30>;
		led,delay_on = <500>;
		led,delay_off = <3500>;
		en-gpio = <&pmi8950_gpios 1 0>;
                i2c-en-gpio = <&pm8953_gpios 5 0>;
                i2c-supply = <&pm8953_l6>;
		redleds{
			linux,name = "red";
			led,mask = /bits/ 8 <0x01>;
			led,max_brightness = <0x3D>;
			led,use-blink;
		};
		greenleds{
			linux,name = "blue";
			/* MODIFIED-BEGIN by hongwei.tian, 2017-01-13,BUG-4005812*/
			led,mask = /bits/ 8 <0x04>;
			led,max_brightness = <0x27>;
			led,use-blink;
		};
		blueleds{
			linux,name = "green";
			led,mask = /bits/ 8 <0x02>;
			/* MODIFIED-END by hongwei.tian,BUG-4005812*/
			led,max_brightness = <0x31>;
			led,use-blink;
		};
	};
/* [PLATFORM]-Add-END by TCTNB.XQJ */
};

/* Changes to msm8993-pinctrl.dtsi for bbry-bbb100-v1 platform */
&tlmm {

	/* GPIO 128 for OMTP/CTIA headset switch signal */
	cross-conn-det {
		cross_conn_det_act: lines_on {
			mux {
				pins = "gpio128";
				function = "gpio";
			};

			config {
				pins = "gpio128";
				drive-strength = <8>;
				output-low;
				bias-pull-down;
			};
		};

		cross_conn_det_sus: lines_off {
			mux {
				pins = "gpio128";
				function = "gpio";
			};

			config {
				pins = "gpio128";
				drive-strength = <2>;
				bias-pull-down;
			};
		};
	};
};

/* Changes to msm8993-audio.dtsi for bbry-bbb100-v1 platform */
&int_codec {

	/* Override sound card name for customization */
	qcom,model = "msm8953-snd-card-bbb100";

	/* Override WSA881X codec name */
	asoc-wsa-codec-names = "wsa881x-i2c-codec.2-000e";

	/* GPIO 128 for OMTP/CTIA headset switch signal */
	qcom,cdc-us-euro-gpios = <&tlmm 128 0>;

	/* Normally open (NO) headset jack */
	qcom,msm-mbhc-hphl-swh = <1>;
	qcom,msm-mbhc-gnd-swh = <1>;

	/* Headset MIC_BIAS2 external capacitor */
	qcom,msm-micbias2-ext-cap;

	/* Override headset mic bias setting */
	qcom,msm-hs-micbias-type = "external";

	/* Override pinctrl sets to remove unused quinary MI2S interface */
	qcom,msm-gpios =
		"pri_i2s",
		"us_eu_gpio",
		"comp_gpio";

	qcom,pinctrl-names =
		"all_off",
		"pri_i2s_act",
		"us_eu_gpio_act",
		"pri_i2s_us_eu_gpio_act",
		"comp_gpio_act",
		"comp_gpio_pri_i2s_act",
		"comp_gpio_us_eu_gpio_act",
		"comp_gpio_pri_i2s_us_eu_gpio_act";

	pinctrl-names =
		"all_off",
		"pri_i2s_act",
		"us_eu_gpio_act",
		"pri_i2s_us_eu_gpio_act",
		"comp_gpio_act",
		"comp_gpio_pri_i2s_act",
		"comp_gpio_us_eu_gpio_act",
		"comp_gpio_pri_i2s_us_eu_gpio_act";

	pinctrl-0 = <&cdc_pdm_lines_sus &cdc_pdm_comp_lines_sus
		&cdc_pdm_lines_2_sus &cross_conn_det_sus>;
	pinctrl-1 = <&cdc_pdm_lines_act &cdc_pdm_comp_lines_sus
		&cdc_pdm_lines_2_act &cross_conn_det_sus>;
	pinctrl-2 = <&cdc_pdm_lines_sus &cdc_pdm_comp_lines_sus
		&cdc_pdm_lines_2_sus &cross_conn_det_act>;
	pinctrl-3 = <&cdc_pdm_lines_act &cdc_pdm_comp_lines_sus
		&cdc_pdm_lines_2_act &cross_conn_det_act>;
	pinctrl-4 = <&cdc_pdm_lines_sus &cdc_pdm_comp_lines_act
		&cdc_pdm_lines_2_sus &cross_conn_det_sus>;
	pinctrl-5 = <&cdc_pdm_lines_act &cdc_pdm_comp_lines_act
		&cdc_pdm_lines_2_act &cross_conn_det_sus>;
	pinctrl-6 = <&cdc_pdm_lines_sus &cdc_pdm_comp_lines_act
		&cdc_pdm_lines_2_sus &cross_conn_det_act>;
	pinctrl-7 = <&cdc_pdm_lines_act &cdc_pdm_comp_lines_act
		&cdc_pdm_lines_2_act &cross_conn_det_act>;
	/delete-property/pinctrl-8;
	/delete-property/pinctrl-9;
	/delete-property/pinctrl-10;
	/delete-property/pinctrl-11;
	/delete-property/pinctrl-12;
	/delete-property/pinctrl-13;
	/delete-property/pinctrl-14;
	/delete-property/pinctrl-15;
};

&wsa881x_i2c_e {
       status = "okay";
};

&wsa881x_i2c_44 {
       status = "okay";
};

&wsa881x_i2c_f {
       status = "okay";
};

&wsa881x_i2c_45 {
       status = "okay";
}; 
&spmi_bus {
	qcom,pm8953@0 {
		/delete-node/pm8953_typec;  /* No need typec node */
		qcom,power-on@800 {
			qcom,pon_2 {
				/delete-property/linux,code;
			};
		};
	};
        /* MODIFIED-BEGIN by yongzhi.li, 2016-11-28,BUG-3610766*/
        qcom,pmi8950@3 {
                flash_led: qcom,leds@d300 {
                       pmi8950_torch0: qcom,torch_0 {
                                /delete-property/qcom,current;
                                qcom,current = <100>;
                       };
                       pmi8950_torch1: qcom,torch_1 {
                                /delete-property/qcom,current;
                                qcom,current = <100>;
                       };
                };
	};
	/* MODIFIED-END by yongzhi.li,BUG-3610766*/
};

/* HWFeatures */
/ {
	/* Attributes must be a string.
	 * Attributes name are limited to 31B.
	 * We append ro.hwf to each attributes and add a .
	 * for delimiter between each level of attributes.
	 *
	 * So the following entry :
	 * hwfeatures_node {
	 *    test1 {
	 *      test2 = "bla";
	 *    }
	 * }
	 *
	 * Will translate into an attribute name ro.hwf.test1.test2
	 */
	hwfeatures_node {
		compatible = "hwfeatures";
		/*
		 * Common NFC properties for all platforms
		 * Platform dependent properties with same property names override
		 * common properties
		 */
		nfc {
			devnode = "/dev/nq-nci";
			hal_module_ids = "nfc_nci.pn54x";
			lib_module_ids = "libnfc-nci";
			config_base = "libnfc-brcm";
			/* These two properties are device specific */
			tuning_config = "mercury";
			allow_signed_fw = "yes";
		};
	};
};
